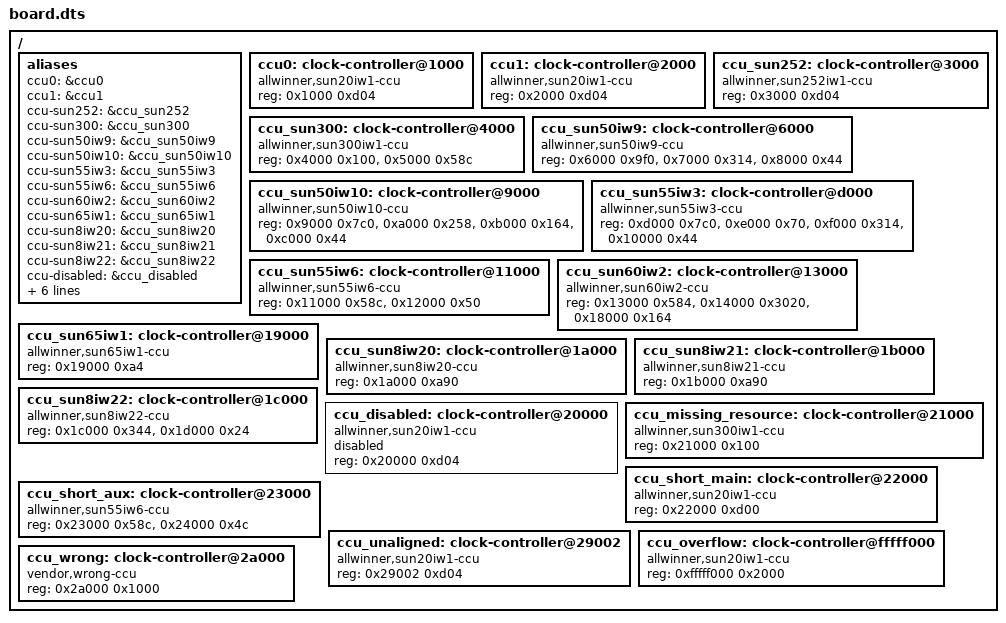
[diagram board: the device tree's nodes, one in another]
/dts-v1/;

/ {
	#address-cells = <1>;
	#size-cells = <1>;

	aliases {
		ccu0 = &ccu0;
		ccu1 = &ccu1;
		ccu-sun252 = &ccu_sun252;
		ccu-sun300 = &ccu_sun300;
		ccu-sun50iw9 = &ccu_sun50iw9;
		ccu-sun50iw10 = &ccu_sun50iw10;
		ccu-sun55iw3 = &ccu_sun55iw3;
		ccu-sun55iw6 = &ccu_sun55iw6;
		ccu-sun60iw2 = &ccu_sun60iw2;
		ccu-sun65iw1 = &ccu_sun65iw1;
		ccu-sun8iw20 = &ccu_sun8iw20;
		ccu-sun8iw21 = &ccu_sun8iw21;
		ccu-sun8iw22 = &ccu_sun8iw22;
		ccu-disabled = &ccu_disabled;
		ccu-missing-resource = &ccu_missing_resource;
		ccu-short-main = &ccu_short_main;
		ccu-short-aux = &ccu_short_aux;
		ccu-unaligned = &ccu_unaligned;
		ccu-overflow = &ccu_overflow;
		ccu-wrong = &ccu_wrong;
	};

	ccu0: clock-controller@1000 {
		compatible = "allwinner,sun20iw1-ccu";
		reg = <0x1000 0xd04>;
		reg-names = "ccu";
		status = "okay";
	};

	ccu1: clock-controller@2000 {
		compatible = "allwinner,sun20iw1-ccu";
		reg = <0x2000 0xd04>;
		reg-names = "ccu";
		status = "okay";
	};

	ccu_sun252: clock-controller@3000 {
		compatible = "allwinner,sun252iw1-ccu";
		reg = <0x3000 0xd04>;
		reg-names = "ccu";
		status = "okay";
	};

	ccu_sun300: clock-controller@4000 {
		compatible = "allwinner,sun300iw1-ccu";
		reg = <0x4000 0x100>, <0x5000 0x58c>;
		reg-names = "app-ccu", "aon-ccu";
		status = "okay";
	};

	ccu_sun50iw9: clock-controller@6000 {
		compatible = "allwinner,sun50iw9-ccu";
		reg = <0x6000 0x9f0>, <0x7000 0x314>, <0x8000 0x44>;
		reg-names = "ccu", "r-prcm", "iommu";
		status = "okay";
	};

	ccu_sun50iw10: clock-controller@9000 {
		compatible = "allwinner,sun50iw10-ccu";
		reg =
			<0x9000 0x7c0>,
			<0xa000 0x258>,
			<0xb000 0x164>,
			<0xc000 0x44>;
		reg-names = "ccu", "r-prcm", "sysctrl", "iommu";
		status = "okay";
	};

	ccu_sun55iw3: clock-controller@d000 {
		compatible = "allwinner,sun55iw3-ccu";
		reg =
			<0xd000 0x7c0>,
			<0xe000 0x70>,
			<0xf000 0x314>,
			<0x10000 0x44>;
		reg-names = "ccu", "cpu-sys-cfg", "r-prcm", "iommu";
		status = "okay";
	};

	ccu_sun55iw6: clock-controller@11000 {
		compatible = "allwinner,sun55iw6-ccu";
		reg = <0x11000 0x58c>, <0x12000 0x50>;
		reg-names = "ccu", "cpu-pll";
		status = "okay";
	};

	ccu_sun60iw2: clock-controller@13000 {
		compatible = "allwinner,sun60iw2-ccu";
		reg = <0x13000 0x584>, <0x14000 0x3020>, <0x18000 0x164>;
		reg-names = "ccu", "cpu-pll", "rtc";
		status = "okay";
	};

	ccu_sun65iw1: clock-controller@19000 {
		compatible = "allwinner,sun65iw1-ccu";
		reg = <0x19000 0xa4>;
		reg-names = "ccu";
		status = "okay";
	};

	ccu_sun8iw20: clock-controller@1a000 {
		compatible = "allwinner,sun8iw20-ccu";
		reg = <0x1a000 0xa90>;
		reg-names = "ccu";
		status = "okay";
	};

	ccu_sun8iw21: clock-controller@1b000 {
		compatible = "allwinner,sun8iw21-ccu";
		reg = <0x1b000 0xa90>;
		reg-names = "ccu";
		status = "okay";
	};

	ccu_sun8iw22: clock-controller@1c000 {
		compatible = "allwinner,sun8iw22-ccu";
		reg = <0x1c000 0x344>, <0x1d000 0x24>;
		reg-names = "ccu", "cpu-pll";
		status = "okay";
	};

	ccu_disabled: clock-controller@20000 {
		compatible = "allwinner,sun20iw1-ccu";
		reg = <0x20000 0xd04>;
		reg-names = "ccu";
		status = "disabled";
	};

	ccu_missing_resource: clock-controller@21000 {
		compatible = "allwinner,sun300iw1-ccu";
		reg = <0x21000 0x100>;
		reg-names = "app-ccu", "aon-ccu";
		status = "okay";
	};

	ccu_short_main: clock-controller@22000 {
		compatible = "allwinner,sun20iw1-ccu";
		reg = <0x22000 0xd00>;
		reg-names = "ccu";
		status = "okay";
	};

	ccu_short_aux: clock-controller@23000 {
		compatible = "allwinner,sun55iw6-ccu";
		reg = <0x23000 0x58c>, <0x24000 0x4c>;
		reg-names = "ccu", "cpu-pll";
		status = "okay";
	};

	ccu_unaligned: clock-controller@29002 {
		compatible = "allwinner,sun20iw1-ccu";
		reg = <0x29002 0xd04>;
		reg-names = "ccu";
		status = "okay";
	};

	ccu_overflow: clock-controller@fffff000 {
		compatible = "allwinner,sun20iw1-ccu";
		reg = <0xfffff000 0x2000>;
		reg-names = "ccu";
		status = "okay";
	};

	ccu_wrong: clock-controller@2a000 {
		compatible = "vendor,wrong-ccu";
		reg = <0x2a000 0x1000>;
		reg-names = "ccu";
		status = "okay";
	};
};
